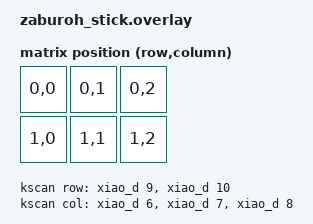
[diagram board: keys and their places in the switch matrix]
// This file was generated from a template. Edit it to match your keyboard.
// See https://zmk.dev/docs/development/hardware-integration/new-shield for more
// instructions.

#include <dt-bindings/zmk/matrix_transform.h>
#include <zephyr/dt-bindings/input/input-event-codes.h>

#include "zaburoh_stick-layouts.dtsi"

&adc {
  status = "okay";
};

/ {
    chosen {
        zmk,physical-layout = &default_layout;
    };

    kscan: kscan {
        // If the hardware does not use a switch matrix, change this to the
        // appropriate driver and update the properties below to match.
        // See https://zmk.dev/docs/config/kscan for supported key scan drivers.
        compatible = "zmk,kscan-gpio-matrix";
        // Set this to "col2row" or "row2col" to match the hardware. If using
        // "row2col", change the col-gpios to (GPIO_ACTIVE_HIGH | GPIO_PULL_DOWN)
        // and the row-gpios to GPIO_ACTIVE_HIGH.
        diode-direction = "col2row";
        wakeup-source;

        // Replace these comments with the GPIO pins in the matrix.
        // See https://zmk.dev/docs/development/hardware-integration/new-shield#shield-overlays
        col-gpios
            = <&xiao_d 6 GPIO_ACTIVE_LOW>
            , <&xiao_d 7 GPIO_ACTIVE_LOW>
            , <&xiao_d 8 GPIO_ACTIVE_LOW>
            ;

        row-gpios
            = <&xiao_d 9 (GPIO_ACTIVE_LOW | GPIO_PULL_UP)>
            , <&xiao_d 10 (GPIO_ACTIVE_LOW | GPIO_PULL_UP)>
            ;
    };

    default_transform: default_transform {
        // See https://zmk.dev/docs/development/hardware-integration/new-shield#matrix-transform
        // for how to configure this
        compatible = "zmk,matrix-transform";
        columns = <3>;
        rows = <2>;

        map = <
            RC(0, 0) RC(0, 1) RC(0, 2)
            RC(1, 0) RC(1, 1) RC(1, 2)
        >;
    };

    joy: analog_joystick {
        compatible = "zmk,analog-input";
        sampling-hz = <100>;

        x-ch {
            io-channels = <&adc 0>;     // ← A0がここ（仮）
            mv-mid = <1630>;            // 3.3Vの中央付近（後で調整）
            mv-min-max = <1600>;
            mv-deadzone = <80>;         // まずは大きめに
            scale-multiplier = <1>;
            scale-divisor = <70>;       // 移動量の速さ（後で調整）
            evt-type = <INPUT_EV_REL>;
            input-code = <INPUT_REL_X>;
            /* invert; */               // 逆なら有効化
        };

        y-ch {
            io-channels = <&adc 1>;     // ← A1がここ（仮）
            mv-mid = <1670>;
            mv-min-max = <1600>;
            mv-deadzone = <80>;
            scale-multiplier = <1>;
            scale-divisor = <70>;
            evt-type = <INPUT_EV_REL>;
            input-code = <INPUT_REL_Y>;
            /* invert; */
        };
    };

    joy_listener: joy_listener {
        compatible = "zmk,input-listener";
        device = <&joy>;
    };
};
